AUTOSAR XML (schema 4-0-3)
package /ComponentTypes
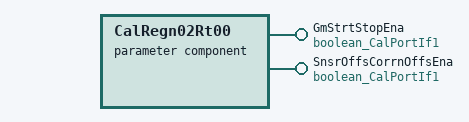
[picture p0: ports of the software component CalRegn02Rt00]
  parameter sw component type CalRegn02Rt00
    provide port GmStrtStopEna: parameter-provide-com-spec{init-value=1, parameter=Logl}, provided-interface=boolean_CalPortIf1
    provide port SnsrOffsCorrnOffsEna: parameter-provide-com-spec{init-value=0, parameter=Logl}, provided-interface=boolean_CalPortIf1
